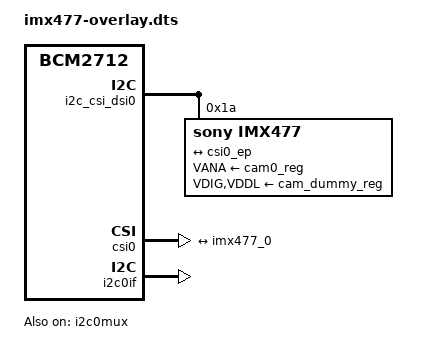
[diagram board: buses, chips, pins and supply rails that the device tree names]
/*
 * Pi HQ Camera (IMX477) Device Tree Overlay
 * Raspberry Pi 5 - MIPI CSI-2 - 12.3MP
 */

/dts-v1/;
/plugin/;

/ {
    compatible = "brcm,bcm2712";
    
    fragment@0 {
        target = <&i2c_csi_dsi0>;
        __overlay__ {
            #address-cells = <1>;
            #size-cells = <0>;
            status = "okay";
            
            imx477: imx477@1a {
                compatible = "sony,imx477";
                reg = <0x1a>;
                status = "okay";
                
                clocks = <&cam0_clk>;
                clock-names = "xclk";
                
                VANA-supply = <&cam0_reg>;
                VDIG-supply = <&cam_dummy_reg>;
                VDDL-supply = <&cam_dummy_reg>;
                
                rotation = <180>;
                orientation = <2>;
                
                port {
                    imx477_0: endpoint {
                        remote-endpoint = <&csi0_ep>;
                        clock-lanes = <0>;
                        data-lanes = <1 2>;
                        clock-noncontinuous;
                        link-frequencies = /bits/ 64 <450000000>;
                    };
                };
            };
        };
    };
    
    fragment@1 {
        target = <&csi0>;
        __overlay__ {
            status = "okay";
            
            port {
                csi0_ep: endpoint {
                    remote-endpoint = <&imx477_0>;
                    data-lanes = <1 2>;
                };
            };
        };
    };
    
    fragment@2 {
        target = <&i2c0if>;
        __overlay__ {
            status = "okay";
        };
    };
    
    fragment@3 {
        target = <&i2c0mux>;
        __overlay__ {
            status = "okay";
        };
    };
    
    __overrides__ {
        rotation = <&imx477>,"rotation:0";
        orientation = <&imx477>,"orientation:0";
        media-controller = <&csi0>,"brcm,media-controller?";
        cam0 = <&imx477>, "status";
    };
};
